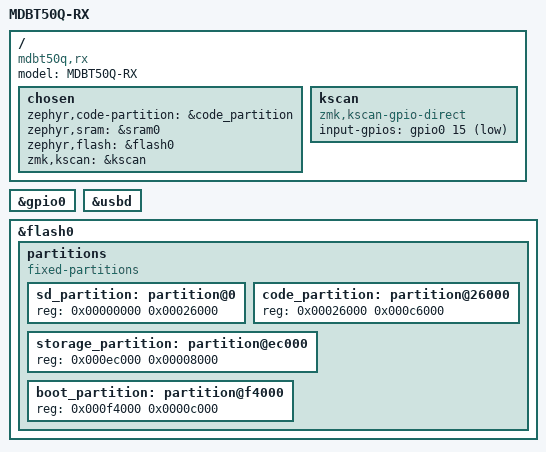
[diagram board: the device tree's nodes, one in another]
/dts-v1/;
#include <nordic/nrf52840_qiaa.dtsi>
#include <dt-bindings/zmk/matrix_transform.h>

/ {
    model = "MDBT50Q-RX";
    compatible = "mdbt50q,rx";

    chosen {
        zephyr,code-partition = &code_partition;
        zephyr,sram = &sram0;
        zephyr,flash = &flash0;
        zmk,kscan = &kscan;
    };

    kscan: kscan {
        compatible = "zmk,kscan-gpio-direct";

        input-gpios = <&gpio0 15 (GPIO_ACTIVE_LOW | GPIO_PULL_UP)>;
    };
};

&gpio0 {
    status = "okay";
};

zephyr_udc0: &usbd {
    status = "okay";
};

&flash0 {
    /*
     * For more information, see:
     * http://docs.zephyrproject.org/latest/devices/dts/flash_partitions.html
     */
    partitions {
        compatible = "fixed-partitions";
        #address-cells = <1>;
        #size-cells = <1>;

        sd_partition: partition@0 {
            reg = <0x00000000 0x00026000>;
        };
        code_partition: partition@26000 {
            reg = <0x00026000 0x000c6000>;
        };

        /*
         * The flash starting at 0x000ec000 and ending at
         * 0x000f3fff is reserved for use by the application.
         */

        /*
         * Storage partition will be used by FCB/LittleFS/NVS
         * if enabled.
         */
        storage_partition: partition@ec000 {
            reg = <0x000ec000 0x00008000>;
        };

        boot_partition: partition@f4000 {
            reg = <0x000f4000 0x0000c000>;
        };
    };
};
